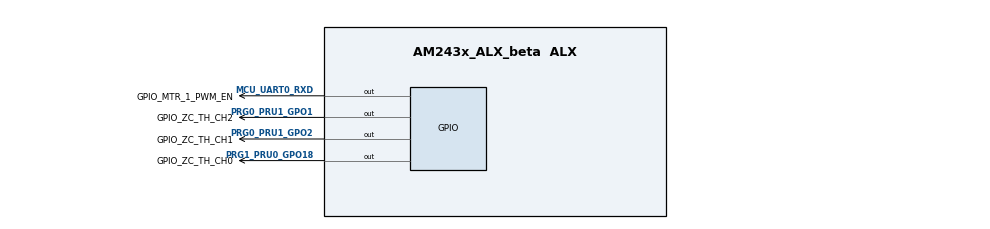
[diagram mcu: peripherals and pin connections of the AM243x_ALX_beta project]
/**
 * @cliArgs --device "AM243x_ALX_beta" --package "ALX" --part "ALX" --context "r5fss0-0" --product "MOTOR_CONTROL_SDK@09.01.00"
 * @versions {"tool":"1.18.0+3266"}
 */

/**
 * Import the modules used in this configuration.
 */
const sdfm       = scripting.addModule("/current_sense/sdfm", {}, false);
const sdfm1      = sdfm.addInstance();
const epwm       = scripting.addModule("/drivers/epwm/epwm", {}, false);
const epwm1      = epwm.addInstance();
const epwm2      = epwm.addInstance();
const gpio       = scripting.addModule("/drivers/gpio/gpio", {}, false);
const gpio1      = gpio.addInstance();
const gpio2      = gpio.addInstance();
const gpio3      = gpio.addInstance();
const gpio4      = gpio.addInstance();
const pruicss    = scripting.addModule("/drivers/pruicss/pruicss", {}, false);
const pruicss1   = pruicss.addInstance();
const pruicss2   = pruicss.addInstance();
const debug_log  = scripting.addModule("/kernel/dpl/debug_log");
const mpu_armv7  = scripting.addModule("/kernel/dpl/mpu_armv7", {}, false);
const mpu_armv71 = mpu_armv7.addInstance();
const mpu_armv72 = mpu_armv7.addInstance();
const mpu_armv73 = mpu_armv7.addInstance();
const mpu_armv74 = mpu_armv7.addInstance();
const mpu_armv75 = mpu_armv7.addInstance();
const pwm        = scripting.addModule("/pru_icssg/pwm", {}, false);
const pwm1       = pwm.addInstance();

/**
 * Write custom configuration values to the imported modules.
 */
sdfm1.$name                  = "CONFIG_SDFM0";
sdfm1.PRU_ICSSG0_PRU.$assign = "PRU_ICSSG0_PRU0";

epwm1.$name            = "CONFIG_EPWM0";
epwm1.EPWM.$assign     = "EHRPWM0";
epwm1.EPWM.SYNCI.$used = false;

epwm2.$name              = "CONFIG_EPWM1";
epwm2.EPWM.SYNCO.$assign = "GPMC0_AD1";
epwm2.EPWM.SYNCO.$used   = false;
epwm2.EPWM.SYNCI.$used   = false;

gpio1.$name                    = "GPIO_MTR_1_PWM_EN";
gpio1.pinDir                   = "OUTPUT";
gpio1.useMcuDomainPeripherals  = true;
gpio1.MCU_GPIO.gpioPin.$assign = "MCU_UART0_RXD";

gpio2.pinDir               = "OUTPUT";
gpio2.$name                = "GPIO_ZC_TH_CH0";
gpio2.GPIO.$assign         = "GPIO0";
gpio2.GPIO.gpioPin.rx      = false;
gpio2.GPIO.gpioPin.$assign = "PRG1_PRU0_GPO18";

gpio3.pinDir               = "OUTPUT";
gpio3.$name                = "GPIO_ZC_TH_CH1";
gpio3.GPIO.gpioPin.rx      = false;
gpio3.GPIO.gpioPin.$assign = "PRG0_PRU1_GPO2";

gpio4.pinDir               = "OUTPUT";
gpio4.$name                = "GPIO_ZC_TH_CH2";
gpio4.GPIO.gpioPin.rx      = false;
gpio4.GPIO.gpioPin.$assign = "PRG0_PRU1_GPO1";

pruicss1.$name                                                                    = "CONFIG_PRU_ICSS0";
pruicss1.coreClk                                                                  = 300000000;
pruicss1.iepClk                                                                   = 300000000;
sdfm1.pru                                                                         = pruicss1;
pruicss1.AdditionalICSSSettings[0].$name                                          = "CONFIG_PRU_ICSS_IO0";
pruicss1.AdditionalICSSSettings[0].PruEcapIO.create(1);
pruicss1.AdditionalICSSSettings[0].PruEcapIO[0].$name                             = "CONFIG_PRU_ICSS_ECAP_IO0";
pruicss1.AdditionalICSSSettings[0].PruEcapIO[0].PRU_ICSSG0_ECAP.$assign           = "PRU_ICSSG0_ECAP0";
pruicss1.AdditionalICSSSettings[0].PruEcapIO[0].PRU_ICSSG0_ECAP.IN_APWM_OUT.$used = true;

pruicss2.$name                                                                      = "CONFIG_PRU_ICSS1";
pruicss2.instance                                                                   = "ICSSG1";
pruicss2.coreClk                                                                    = 300000000;
pruicss2.iepClk                                                                     = 300000000;
pruicss2.AdditionalICSSSettings[0].$name                                            = "CONFIG_PRU_ICSS_IO1";
pruicss2.AdditionalICSSSettings[0].PruIepIO.create(1);
pruicss2.AdditionalICSSSettings[0].PruIepIO[0].$name                                = "CONFIG_PRU_ICSS_IEP_IO0";
pruicss2.AdditionalICSSSettings[0].PruIepIO[0].instance                             = "ICSSG1";
pruicss2.AdditionalICSSSettings[0].PruIepIO[0].PRU_ICSSG1_IEP.$assign               = "PRU_ICSSG1_IEP0";
pruicss2.AdditionalICSSSettings[0].PruIepIO[0].PRU_ICSSG1_IEP.EDC_SYNC_OUT0.$assign = "PRG1_PRU0_GPO19";
pruicss2.AdditionalICSSSettings[0].PruIepIO[0].PRU_ICSSG1_IEP.EDC_SYNC_OUT0.$used   = true;
pruicss2.AdditionalICSSSettings[0].PruIepIO[0].PRU_ICSSG1_IEP.EDC_SYNC_OUT1.$assign = "PRG1_PRU0_GPO17";
pruicss2.AdditionalICSSSettings[0].PruIepIO[0].PRU_ICSSG1_IEP.EDC_SYNC_OUT1.$used   = true;

debug_log.enableUartLog        = true;
debug_log.uartLog.$name        = "CONFIG_UART_CONSOLE";
debug_log.uartLog.UART.$assign = "USART0";

mpu_armv71.$name             = "CONFIG_MPU_REGION0";
mpu_armv71.size              = 31;
mpu_armv71.attributes        = "Device";
mpu_armv71.accessPermissions = "Supervisor RD+WR, User RD";
mpu_armv71.allowExecute      = false;

mpu_armv72.$name             = "CONFIG_MPU_REGION1";
mpu_armv72.size              = 15;
mpu_armv72.accessPermissions = "Supervisor RD+WR, User RD";

mpu_armv73.$name             = "CONFIG_MPU_REGION2";
mpu_armv73.baseAddr          = 0x41010000;
mpu_armv73.size              = 15;
mpu_armv73.accessPermissions = "Supervisor RD+WR, User RD";

mpu_armv74.$name             = "CONFIG_MPU_REGION3";
mpu_armv74.accessPermissions = "Supervisor RD+WR, User RD";
mpu_armv74.baseAddr          = 0x70000000;
mpu_armv74.size              = 21;

mpu_armv75.$name             = "CONFIG_MPU_REGION4";
mpu_armv75.baseAddr          = 0x60000000;
mpu_armv75.size              = 28;
mpu_armv75.accessPermissions = "Supervisor RD, User RD";

pwm1.$name                       = "CONFIG_PRU_ICSS_PWM0";
pwm1.PRU_ICSSG0_PWM.$assign      = "PRU_ICSSG0_PWM0";
pwm1.PRU_ICSSG0_PWM.TZ_OUT.$used = true;

/**
 * Pinmux solution for unlocked pins/peripherals. This ensures that minor changes to the automatic solver in a future
 * version of the tool will not impact the pinmux you originally saw.  These lines can be completely deleted in order to
 * re-solve from scratch.
 */
sdfm1.PRU_ICSSG0_PRU.GPI16.$suggestSolution                                                  = "PRG0_PRU0_GPO16";
sdfm1.PRU_ICSSG0_PRU.GPI1.$suggestSolution                                                   = "PRG0_PRU0_GPO1";
sdfm1.PRU_ICSSG0_PRU.GPI3.$suggestSolution                                                   = "PRG0_PRU0_GPO3";
sdfm1.PRU_ICSSG0_PRU.GPI5.$suggestSolution                                                   = "PRG0_PRU0_GPO5";
epwm1.EPWM.A.$suggestSolution                                                                = "GPMC0_AD3";
epwm1.EPWM.B.$suggestSolution                                                                = "GPMC0_AD4";
epwm1.EPWM.SYNCO.$suggestSolution                                                            = "GPMC0_AD1";
epwm2.EPWM.$suggestSolution                                                                  = "EHRPWM1";
epwm2.EPWM.A.$suggestSolution                                                                = "GPMC0_AD5";
epwm2.EPWM.B.$suggestSolution                                                                = "GPMC0_AD6";
gpio1.MCU_GPIO.$suggestSolution                                                              = "MCU_GPIO0";
gpio3.GPIO.$suggestSolution                                                                  = "GPIO1";
gpio4.GPIO.$suggestSolution                                                                  = "GPIO1";
pruicss1.AdditionalICSSSettings[0].PruEcapIO[0].PRU_ICSSG0_ECAP.IN_APWM_OUT.$suggestSolution = "PRG0_PRU1_GPO15";
debug_log.uartLog.UART.RXD.$suggestSolution                                                  = "UART0_RXD";
debug_log.uartLog.UART.TXD.$suggestSolution                                                  = "UART0_TXD";
pwm1.PRU_ICSSG0_PWM.TZ_OUT.$suggestSolution                                                  = "PRG0_PRU0_GPO19";
